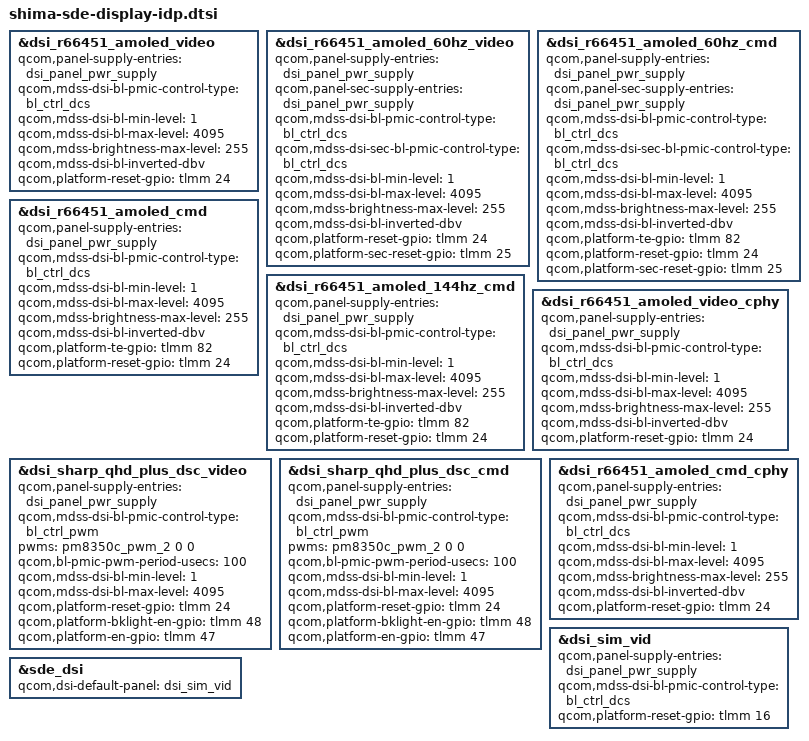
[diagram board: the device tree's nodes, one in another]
#include "shima-sde-display.dtsi"

&dsi_r66451_amoled_video {
	qcom,panel-supply-entries = <&dsi_panel_pwr_supply>;
	qcom,mdss-dsi-bl-pmic-control-type = "bl_ctrl_dcs";
	qcom,mdss-dsi-bl-min-level = <1>;
	qcom,mdss-dsi-bl-max-level = <4095>;
	qcom,mdss-brightness-max-level = <255>;
	qcom,mdss-dsi-bl-inverted-dbv;
	qcom,platform-reset-gpio = <&tlmm 24 0>;
};

&dsi_r66451_amoled_60hz_video {
	qcom,panel-supply-entries = <&dsi_panel_pwr_supply>;
	qcom,panel-sec-supply-entries = <&dsi_panel_pwr_supply>;
	qcom,mdss-dsi-bl-pmic-control-type = "bl_ctrl_dcs";
	qcom,mdss-dsi-sec-bl-pmic-control-type = "bl_ctrl_dcs";
	qcom,mdss-dsi-bl-min-level = <1>;
	qcom,mdss-dsi-bl-max-level = <4095>;
	qcom,mdss-brightness-max-level = <255>;
	qcom,mdss-dsi-bl-inverted-dbv;
	qcom,platform-reset-gpio = <&tlmm 24 0>;
	qcom,platform-sec-reset-gpio = <&tlmm 25 0>;
};

&dsi_r66451_amoled_60hz_cmd {
	qcom,panel-supply-entries = <&dsi_panel_pwr_supply>;
	qcom,panel-sec-supply-entries = <&dsi_panel_pwr_supply>;
	qcom,mdss-dsi-bl-pmic-control-type = "bl_ctrl_dcs";
	qcom,mdss-dsi-sec-bl-pmic-control-type = "bl_ctrl_dcs";
	qcom,mdss-dsi-bl-min-level = <1>;
	qcom,mdss-dsi-bl-max-level = <4095>;
	qcom,mdss-brightness-max-level = <255>;
	qcom,mdss-dsi-bl-inverted-dbv;
	qcom,platform-te-gpio = <&tlmm 82 0>;
	qcom,platform-reset-gpio = <&tlmm 24 0>;
	qcom,platform-sec-reset-gpio = <&tlmm 25 0>;
};

&dsi_r66451_amoled_cmd {
	qcom,panel-supply-entries = <&dsi_panel_pwr_supply>;
	qcom,mdss-dsi-bl-pmic-control-type = "bl_ctrl_dcs";
	qcom,mdss-dsi-bl-min-level = <1>;
	qcom,mdss-dsi-bl-max-level = <4095>;
	qcom,mdss-brightness-max-level = <255>;
	qcom,mdss-dsi-bl-inverted-dbv;
	qcom,platform-te-gpio = <&tlmm 82 0>;
	qcom,platform-reset-gpio = <&tlmm 24 0>;
};

&dsi_r66451_amoled_144hz_cmd {
	qcom,panel-supply-entries = <&dsi_panel_pwr_supply>;
	qcom,mdss-dsi-bl-pmic-control-type = "bl_ctrl_dcs";
	qcom,mdss-dsi-bl-min-level = <1>;
	qcom,mdss-dsi-bl-max-level = <4095>;
	qcom,mdss-brightness-max-level = <255>;
	qcom,mdss-dsi-bl-inverted-dbv;
	qcom,platform-te-gpio = <&tlmm 82 0>;
	qcom,platform-reset-gpio = <&tlmm 24 0>;
};

&dsi_r66451_amoled_video_cphy {
	qcom,panel-supply-entries = <&dsi_panel_pwr_supply>;
	qcom,mdss-dsi-bl-pmic-control-type = "bl_ctrl_dcs";
	qcom,mdss-dsi-bl-min-level = <1>;
	qcom,mdss-dsi-bl-max-level = <4095>;
	qcom,mdss-brightness-max-level = <255>;
	qcom,mdss-dsi-bl-inverted-dbv;
	qcom,platform-reset-gpio = <&tlmm 24 0>;
};

&dsi_sharp_qhd_plus_dsc_video {
	qcom,panel-supply-entries = <&dsi_panel_pwr_supply>;
	qcom,mdss-dsi-bl-pmic-control-type = "bl_ctrl_pwm";
	pwms = <&pm8350c_pwm_2 0 0>;
	qcom,bl-pmic-pwm-period-usecs = <100>;
	qcom,mdss-dsi-bl-min-level = <1>;
	qcom,mdss-dsi-bl-max-level = <4095>;
	qcom,platform-reset-gpio = <&tlmm 24 0>;
	qcom,platform-bklight-en-gpio = <&tlmm 48 0>;
	qcom,platform-en-gpio = <&tlmm 47 0>;
};

&dsi_sharp_qhd_plus_dsc_cmd {
	qcom,panel-supply-entries = <&dsi_panel_pwr_supply>;
	qcom,mdss-dsi-bl-pmic-control-type = "bl_ctrl_pwm";
	pwms = <&pm8350c_pwm_2 0 0>;
	qcom,bl-pmic-pwm-period-usecs = <100>;
	qcom,mdss-dsi-bl-min-level = <1>;
	qcom,mdss-dsi-bl-max-level = <4095>;
	qcom,platform-reset-gpio = <&tlmm 24 0>;
	qcom,platform-bklight-en-gpio = <&tlmm 48 0>;
	qcom,platform-en-gpio = <&tlmm 47 0>;
};

&dsi_r66451_amoled_cmd_cphy {
	qcom,panel-supply-entries = <&dsi_panel_pwr_supply>;
	qcom,mdss-dsi-bl-pmic-control-type = "bl_ctrl_dcs";
	qcom,mdss-dsi-bl-min-level = <1>;
	qcom,mdss-dsi-bl-max-level = <4095>;
	qcom,mdss-brightness-max-level = <255>;
	qcom,mdss-dsi-bl-inverted-dbv;
	qcom,platform-reset-gpio = <&tlmm 24 0>;
};

&dsi_sim_vid {
	qcom,panel-supply-entries = <&dsi_panel_pwr_supply>;
	qcom,mdss-dsi-bl-pmic-control-type = "bl_ctrl_dcs";
	qcom,platform-reset-gpio = <&tlmm 16 0>;
};

&sde_dsi {
	qcom,dsi-default-panel = <&dsi_sim_vid>;
};
